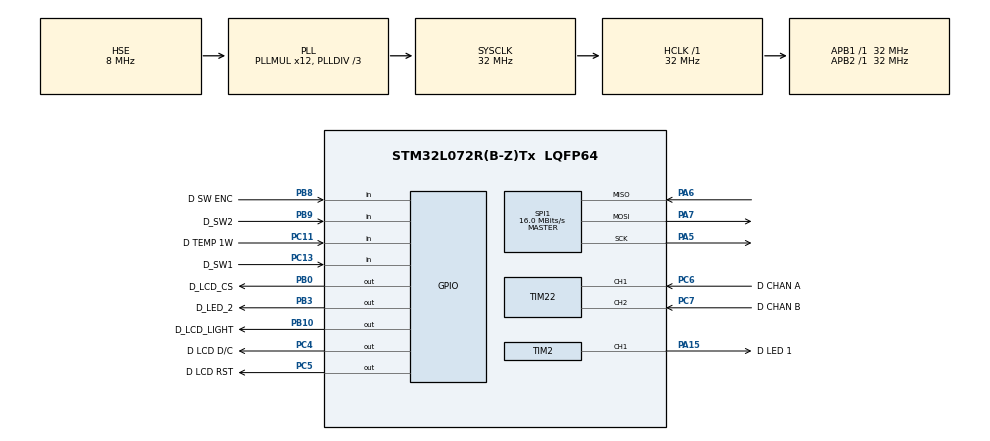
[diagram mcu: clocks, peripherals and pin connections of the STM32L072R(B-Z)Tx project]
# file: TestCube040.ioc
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Mcu.Family=STM32L0
Mcu.Name=STM32L072R(B-Z)Tx
Mcu.Package=LQFP64
PA13.Mode=Serial_Wire
PA13.Signal=SYS_SWDIO
PA14.Mode=Serial_Wire
PA14.Signal=SYS_SWCLK
PA15.GPIO_Label=D LED 1
PA15.Signal=S_TIM2_CH1
PA5.Mode=Full_Duplex_Master
PA5.Signal=SPI1_SCK
PA6.Mode=Full_Duplex_Master
PA6.Signal=SPI1_MISO
PA7.Mode=Full_Duplex_Master
PA7.Signal=SPI1_MOSI
PB0.GPIO_Label=D_LCD_CS
PB0.Signal=GPIO_Output
PB10.GPIO_Label=D_LCD_LIGHT
PB10.Signal=GPIO_Output
PB11.GPIO_Label=D SWO
PB11.Signal=EVENTOUT
PB3.GPIO_Label=D_LED_2
PB3.Signal=GPIO_Output
PB8.GPIO_Label=D SW ENC
PB8.Signal=GPIO_Input
PB9.GPIO_Label=D_SW2
PB9.Signal=GPIO_Input
PC11.GPIO_Label=D TEMP 1W
PC11.Signal=GPIO_Input
PC13.GPIO_Label=D_SW1
PC13.Signal=GPIO_Input
PC14-OSC32_IN.Mode=LSE-External-Oscillator
PC14-OSC32_IN.Signal=RCC_OSC32_IN
PC15-OSC32_OUT.Mode=LSE-External-Oscillator
PC15-OSC32_OUT.Signal=RCC_OSC32_OUT
PC4.GPIO_Label=D LCD D/C
PC4.Signal=GPIO_Output
PC5.GPIO_Label=D LCD RST
PC5.Signal=GPIO_Output
PC6.GPIO_Label=D CHAN A
PC6.Signal=S_TIM22_CH1
PC7.GPIO_Label=D CHAN B
PC7.Signal=S_TIM22_CH2
PH0-OSC_IN.Mode=HSE-External-Oscillator
PH0-OSC_IN.Signal=RCC_OSC_IN
PH1-OSC_OUT.Mode=HSE-External-Oscillator
PH1-OSC_OUT.Signal=RCC_OSC_OUT
ProjectManager.HeapSize=0x200
ProjectManager.StackSize=0x400
ProjectManager.TargetToolchain=SW4STM32
RCC.AHBFreq_Value=32000000
RCC.APB1Freq_Value=32000000
RCC.APB1TimFreq_Value=32000000
RCC.APB2Freq_Value=32000000
RCC.APB2TimFreq_Value=32000000
RCC.HCLKFreq_Value=32000000
RCC.HSE_VALUE=8000000
RCC.HSI16_VALUE=16000000
RCC.HSI48_VALUE=48000000
RCC.HSI_VALUE=16000000
RCC.MSI_VALUE=2097000
RCC.PLLDIV=RCC_PLLDIV_3
RCC.PLLMUL=RCC_PLLMUL_12
RCC.PLLSourceVirtual=RCC_PLLSOURCE_HSE
RCC.RTCClockSelectionVirtual=RCC_RTCCLKSOURCE_LSE
RCC.SYSCLKFreq_VALUE=32000000
RCC.SYSCLKSource=RCC_SYSCLKSOURCE_PLLCLK
RCC.VCOOutputFreq_Value=96000000
SH.S_TIM22_CH1.0=TIM22_CH1,Encoder_Interface
SH.S_TIM22_CH2.0=TIM22_CH2,Encoder_Interface
SH.S_TIM2_CH1.0=TIM2_CH1,PWM Generation1 CH1
SPI1.CalculateBaudRate=16.0 MBits/s
SPI1.Mode=SPI_MODE_MASTER
board=TestCube040

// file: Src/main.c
/**
  ******************************************************************************
  * File Name          : main.c
  * Description        : Main program body
  ******************************************************************************
  *
  * COPYRIGHT(c) 2016 STMicroelectronics
  *
  * Redistribution and use in source and binary forms, with or without modification,
  * are permitted provided that the following conditions are met:
  *   1. Redistributions of source code must retain the above copyright notice,
  *      this list of conditions and the following disclaimer.
  *   2. Redistributions in binary form must reproduce the above copyright notice,
  *      this list of conditions and the following disclaimer in the documentation
  *      and/or other materials provided with the distribution.
  *   3. Neither the name of STMicroelectronics nor the names of its contributors
  *      may be used to endorse or promote products derived from this software
  *      without specific prior written permission.
  *
  * THIS SOFTWARE IS PROVIDED BY THE COPYRIGHT HOLDERS AND CONTRIBUTORS "AS IS"
  * AND ANY EXPRESS OR IMPLIED WARRANTIES, INCLUDING, BUT NOT LIMITED TO, THE
  * IMPLIED WARRANTIES OF MERCHANTABILITY AND FITNESS FOR A PARTICULAR PURPOSE ARE
  * DISCLAIMED. IN NO EVENT SHALL THE COPYRIGHT HOLDER OR CONTRIBUTORS BE LIABLE
  * FOR ANY DIRECT, INDIRECT, INCIDENTAL, SPECIAL, EXEMPLARY, OR CONSEQUENTIAL
  * DAMAGES (INCLUDING, BUT NOT LIMITED TO, PROCUREMENT OF SUBSTITUTE GOODS OR
  * SERVICES; LOSS OF USE, DATA, OR PROFITS; OR BUSINESS INTERRUPTION) HOWEVER
  * CAUSED AND ON ANY THEORY OF LIABILITY, WHETHER IN CONTRACT, STRICT LIABILITY,
  * OR TORT (INCLUDING NEGLIGENCE OR OTHERWISE) ARISING IN ANY WAY OUT OF THE USE
  * OF THIS SOFTWARE, EVEN IF ADVISED OF THE POSSIBILITY OF SUCH DAMAGE.
  *
  ******************************************************************************
  */
#include "main.h"
#include "stm32l0xx_hal.h"
#include "spi.h"
#include "tim.h"
#include "gpio.h"

#define  PERIOD_VALUE       (uint32_t)(700 - 1)  /* Period Value  */
#define  PULSE1_VALUE       (uint32_t)(PERIOD_VALUE/2)        /* Capture Compare 1 Value  */

/* USER CODE BEGIN PV */
/* Private variables ---------------------------------------------------------*/
/* Timer handler declaration */
TIM_HandleTypeDef    TimHandle;

/* Timer Output Compare Configuration Structure declaration */
TIM_OC_InitTypeDef sConfig;

/* Counter Prescaler value */
uint32_t uhPrescalerValue = 0;

/* USER CODE END PV */

void SystemClock_Config(void);
void Error_Handler(void);

/* USER CODE BEGIN PFP */
/* Private function prototypes -----------------------------------------------*/

/* USER CODE END PFP */

/* USER CODE BEGIN 0 */
//this code will togle with GPIO output
void blik(){
	HAL_GPIO_TogglePin(D_LCD_LIGHT_GPIO_Port,D_LCD_LIGHT_Pin);
}
/* USER CODE END 0 */

int main(void)
{

  /* MCU Configuration----------------------------------------------------------*/

  /* Reset of all peripherals, Initializes the Flash interface and the Systick. */
  HAL_Init();

  /* Configure the system clock */
  SystemClock_Config();

  /* Initialize all configured peripherals */
  MX_GPIO_Init();
  MX_SPI1_Init();
  MX_TIM2_Init();
  MX_TIM22_Init();

  /* USER CODE BEGIN 2 */
  /* Compute the prescaler value to have TIM2 counter clock equal to 2000000 Hz */
   uhPrescalerValue = (uint32_t)(SystemCoreClock / 2000000) - 1;

  blik();
  /* USER CODE END 2 */

  /* Set the pulse value for channel 1 */
  sConfig.Pulse = PULSE1_VALUE;
  if (HAL_TIM_PWM_ConfigChannel(&TimHandle, &sConfig, TIM_CHANNEL_1) != HAL_OK)
  {
    /* Configuration Error */
    Error_Handler();
  }

  if (HAL_TIM_PWM_Start(&TimHandle, TIM_CHANNEL_1) != HAL_OK)
    {
      /* PWM Generation Error */
      Error_Handler();
    }

  /* Infinite loop */
  while (1)
  {

if(!HAL_GPIO_ReadPin(D_SW2_GPIO_Port,D_SW2_Pin))
	HAL_GPIO_TogglePin(D_LED_2_GPIO_Port,D_LED_2_Pin);
if(!HAL_GPIO_ReadPin(D_SW1_GPIO_Port,D_SW1_Pin))
	blik();

HAL_Delay(200); //wait in ms
  }

}

/** System Clock Configuration
*/
void SystemClock_Config(void)
{

  RCC_OscInitTypeDef RCC_OscInitStruct;
  RCC_ClkInitTypeDef RCC_ClkInitStruct;

    /**Configure the main internal regulator output voltage
    */
  __HAL_PWR_VOLTAGESCALING_CONFIG(PWR_REGULATOR_VOLTAGE_SCALE1);

    /**Initializes the CPU, AHB and APB busses clocks
    */
  RCC_OscInitStruct.OscillatorType = RCC_OSCILLATORTYPE_HSE;
  RCC_OscInitStruct.HSEState = RCC_HSE_ON;
  RCC_OscInitStruct.PLL.PLLState = RCC_PLL_ON;
  RCC_OscInitStruct.PLL.PLLSource = RCC_PLLSOURCE_HSE;
  RCC_OscInitStruct.PLL.PLLMUL = RCC_PLLMUL_12;
  RCC_OscInitStruct.PLL.PLLDIV = RCC_PLLDIV_3;
  if (HAL_RCC_OscConfig(&RCC_OscInitStruct) != HAL_OK)
  {
    Error_Handler();
  }

    /**Initializes the CPU, AHB and APB busses clocks
    */
  RCC_ClkInitStruct.ClockType = RCC_CLOCKTYPE_HCLK|RCC_CLOCKTYPE_SYSCLK
                              |RCC_CLOCKTYPE_PCLK1|RCC_CLOCKTYPE_PCLK2;
  RCC_ClkInitStruct.SYSCLKSource = RCC_SYSCLKSOURCE_PLLCLK;
  RCC_ClkInitStruct.AHBCLKDivider = RCC_SYSCLK_DIV1;
  RCC_ClkInitStruct.APB1CLKDivider = RCC_HCLK_DIV1;
  RCC_ClkInitStruct.APB2CLKDivider = RCC_HCLK_DIV1;

  if (HAL_RCC_ClockConfig(&RCC_ClkInitStruct, FLASH_LATENCY_1) != HAL_OK)
  {
    Error_Handler();
  }

    /**Configure the Systick interrupt time
    */
  HAL_SYSTICK_Config(HAL_RCC_GetHCLKFreq()/1000);

    /**Configure the Systick
    */
  HAL_SYSTICK_CLKSourceConfig(SYSTICK_CLKSOURCE_HCLK);

  /* SysTick_IRQn interrupt configuration */
  HAL_NVIC_SetPriority(SysTick_IRQn, 0, 0);
}

void Error_Handler(void)
{
  while(1)
  {
  }
}

/************************ (C) COPYRIGHT STMicroelectronics *****END OF FILE****/
